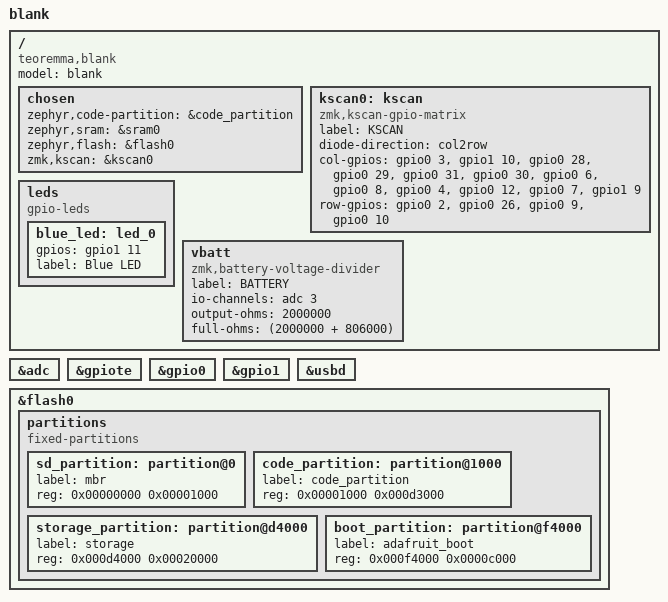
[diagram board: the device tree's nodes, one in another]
/*
 * Copyright (c) 2021 teoremma
 *
 * SPDX-License-Identifier: MIT
 */

/dts-v1/;
#include <nordic/nrf52840_qiaa.dtsi>

/ {
	model = "blank";
	compatible = "teoremma,blank";

	chosen {
		zephyr,code-partition = &code_partition;
		zephyr,sram = &sram0;
		zephyr,flash = &flash0;
		zmk,kscan = &kscan0;
	};

	kscan0: kscan {
		compatible = "zmk,kscan-gpio-matrix";
		label = "KSCAN";

		diode-direction = "col2row";
        col-gpios
			= <&gpio0 3  GPIO_ACTIVE_HIGH>
			, <&gpio1 10 GPIO_ACTIVE_HIGH>
			, <&gpio0 28 GPIO_ACTIVE_HIGH>
			, <&gpio0 29 GPIO_ACTIVE_HIGH>
			, <&gpio0 31 GPIO_ACTIVE_HIGH>
			, <&gpio0 30 GPIO_ACTIVE_HIGH>
			, <&gpio0 6  GPIO_ACTIVE_HIGH>
			, <&gpio0 8  GPIO_ACTIVE_HIGH>
			, <&gpio0 4  GPIO_ACTIVE_HIGH>
			, <&gpio0 12 GPIO_ACTIVE_HIGH>
			, <&gpio0 7  GPIO_ACTIVE_HIGH>
			, <&gpio1 9  GPIO_ACTIVE_HIGH>
			;
		row-gpios
			= <&gpio0 2 (GPIO_ACTIVE_HIGH | GPIO_PULL_DOWN)>
			, <&gpio0 26 (GPIO_ACTIVE_HIGH | GPIO_PULL_DOWN)>
			, <&gpio0 9 (GPIO_ACTIVE_HIGH | GPIO_PULL_DOWN)>
			, <&gpio0 10 (GPIO_ACTIVE_HIGH | GPIO_PULL_DOWN)>
			;
		
	};

	leds {
		compatible = "gpio-leds";
		blue_led: led_0 {
			gpios = <&gpio1 11 GPIO_ACTIVE_HIGH>;
			label = "Blue LED";
		};
	};

	vbatt {
		compatible = "zmk,battery-voltage-divider";
		label = "BATTERY";
		io-channels = <&adc 3>;
		output-ohms = <2000000>;
		full-ohms = <(2000000 + 806000)>;
	};
};

&adc {
	status = "okay";
};

&gpiote {
	status = "okay";
};

&gpio0 {
	status = "okay";
};

&gpio1 {
	status = "okay";
};

&usbd {
	status = "okay";
};

&flash0 {
	/*
	 * For more information, see:
	 * http://docs.zephyrproject.org/latest/devices/dts/flash_partitions.html
	 */
	partitions {
		compatible = "fixed-partitions";
		#address-cells = <1>;
		#size-cells = <1>;

		sd_partition: partition@0 {
			label = "mbr";
			reg = <0x00000000 0x00001000>;
		};

		code_partition: partition@1000 {
			label = "code_partition";
			reg = <0x00001000 0x000d3000>;
		};

		/*
		 * The flash starting at 0x000d4000 and ending at
		 * 0x000f3fff is reserved for use by the application.
		 */

		/*
		 * Storage partition will be used by FCB/LittleFS/NVS
		 * if enabled.
		 */
		storage_partition: partition@d4000 {
			label = "storage";
			reg = <0x000d4000 0x00020000>;
		};

		boot_partition: partition@f4000 {
			label = "adafruit_boot";
			reg = <0x000f4000 0x0000c000>;
		};
	};
};
